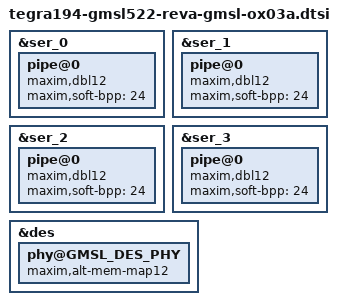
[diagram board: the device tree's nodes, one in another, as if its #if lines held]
#if GMSL_CAMERA_NUM >= 1
&ser_0 {
	pipe@0 {
		maxim,dbl12;
		maxim,soft-bpp = <24>;
	};
};
#endif

#if GMSL_CAMERA_NUM >= 2
&ser_1 {
	pipe@0 {
		maxim,dbl12;
		maxim,soft-bpp = <24>;
	};
};
#endif

#if GMSL_CAMERA_NUM >= 3
&ser_2 {
	pipe@0 {
		maxim,dbl12;
		maxim,soft-bpp = <24>;
	};
};
#endif

#if GMSL_CAMERA_NUM >= 4
&ser_3 {
	pipe@0 {
		maxim,dbl12;
		maxim,soft-bpp = <24>;
	};
};
#endif

&des {
	phy@GMSL_DES_PHY {
		maxim,alt-mem-map12;
	};
};
